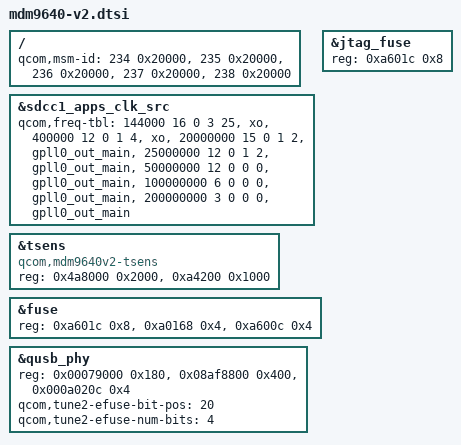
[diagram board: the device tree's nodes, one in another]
/* Copyright (c) 2015, The Linux Foundation. All rights reserved.
 *
 * This program is free software; you can redistribute it and/or modify
 * it under the terms of the GNU General Public License version 2 and
 * only version 2 as published by the Free Software Foundation.
 *
 * This program is distributed in the hope that it will be useful,
 * but WITHOUT ANY WARRANTY; without even the implied warranty of
 * MERCHANTABILITY or FITNESS FOR A PARTICULAR PURPOSE.  See the
 * GNU General Public License for more details.
 */

#include "mdm9640.dtsi"

/ {
	qcom,msm-id = <234 0x20000>, <235 0x20000>, <236 0x20000>,
		      <237 0x20000>, <238 0x20000>;
};

&sdcc1_apps_clk_src {
	qcom,freq-tbl =
		<    144000   16    0    3    25 &xo>,
		<    400000   12    0    1     4 &xo>,
		<  20000000   15    0    1     2 &gpll0_out_main>,
		<  25000000   12    0    1     2 &gpll0_out_main>,
		<  50000000   12    0    0     0 &gpll0_out_main>,
		< 100000000    6    0    0     0 &gpll0_out_main>,
		< 200000000    3    0    0     0 &gpll0_out_main>,
		<>;
};

&jtag_fuse {
	reg = <0xa601c 0x8>;
	reg-names = "fuse-base";
};

&tsens {
	reg = <0x4a8000 0x2000>,
		<0xa4200 0x1000>;
	compatible = "qcom,mdm9640v2-tsens";
	reg-names = "tsens_physical", "tsens_eeprom_physical";
};

&fuse {
	reg = <0xa601c 0x8>,
		<0xa0168 0x4>,
		<0xa600c 0x4>;
	reg-names = "fuse-base", "nidnt-fuse-base", "qpdi-fuse-base";
};

&qusb_phy {
	reg = <0x00079000 0x180>,
	    <0x08af8800 0x400>,
	    <0x000a020c 0x4>;
	reg-names = "qusb_phy_base",
		"qscratch_base",
		"tune2_efuse_addr";
	qcom,tune2-efuse-bit-pos = <20>;
	qcom,tune2-efuse-num-bits = <4>;
};
